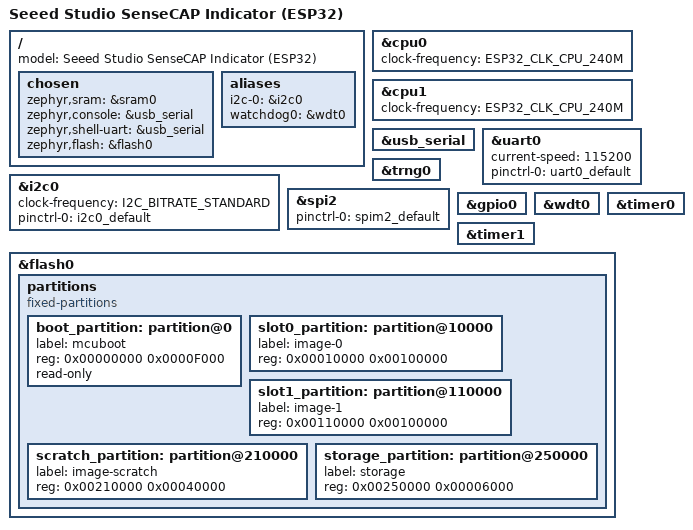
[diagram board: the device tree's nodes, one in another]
/*
 * Copyright (c) 2023 Seeed Studio inc.
 *
 * SPDX-License-Identifier: Apache-2.0
 */

/dts-v1/;

#include <espressif/esp32s3/esp32s3_r8.dtsi>
#include "sensecap_indicator_esp32-pinctrl.dtsi"

/ {
	model = "Seeed Studio SenseCAP Indicator (ESP32)";
	//compatible = "seeed,sensecap-indicator-esp32";

	chosen {
		zephyr,sram = &sram0;
		zephyr,console = &usb_serial;
		zephyr,shell-uart = &usb_serial;
		zephyr,flash = &flash0;
	};

	aliases {
		i2c-0 = &i2c0;
		watchdog0 = &wdt0;
	};

};

&cpu0 {
	clock-frequency = <ESP32_CLK_CPU_240M>;
};

&cpu1 {
	clock-frequency = <ESP32_CLK_CPU_240M>;
};

&usb_serial {
	status = "okay";
};

&uart0 {
	status = "okay";
	current-speed = <115200>;
	pinctrl-0 = <&uart0_default>;
	pinctrl-names = "default";
};

&i2c0 {
	status = "okay";
	clock-frequency = <I2C_BITRATE_STANDARD>;
	pinctrl-0 = <&i2c0_default>;
	pinctrl-names = "default";
};

&trng0 {
	status = "okay";
};

&spi2 {
	#address-cells = <1>;
	#size-cells = <0>;
	status = "okay";
	pinctrl-0 = <&spim2_default>;
	pinctrl-names = "default";
};

&gpio0 {
	status = "okay";
};

&wdt0 {
	status = "okay";
};

&timer0 {
	status = "okay";
};

&timer1 {
	status = "okay";
};

&flash0 {
	status = "okay";
	partitions {
		compatible = "fixed-partitions";
		#address-cells = <1>;
		#size-cells = <1>;

		boot_partition: partition@0 {
			label = "mcuboot";
			reg = <0x00000000 0x0000F000>;
			read-only;
		};

		slot0_partition: partition@10000 {
			label = "image-0";
			reg = <0x00010000 0x00100000>;
		};

		slot1_partition: partition@110000 {
			label = "image-1";
			reg = <0x00110000 0x00100000>;
		};

		scratch_partition: partition@210000 {
			label = "image-scratch";
			reg = <0x00210000 0x00040000>;
		};

		storage_partition: partition@250000 {
			label = "storage";
			reg = <0x00250000 0x00006000>;
		};
	};
};
